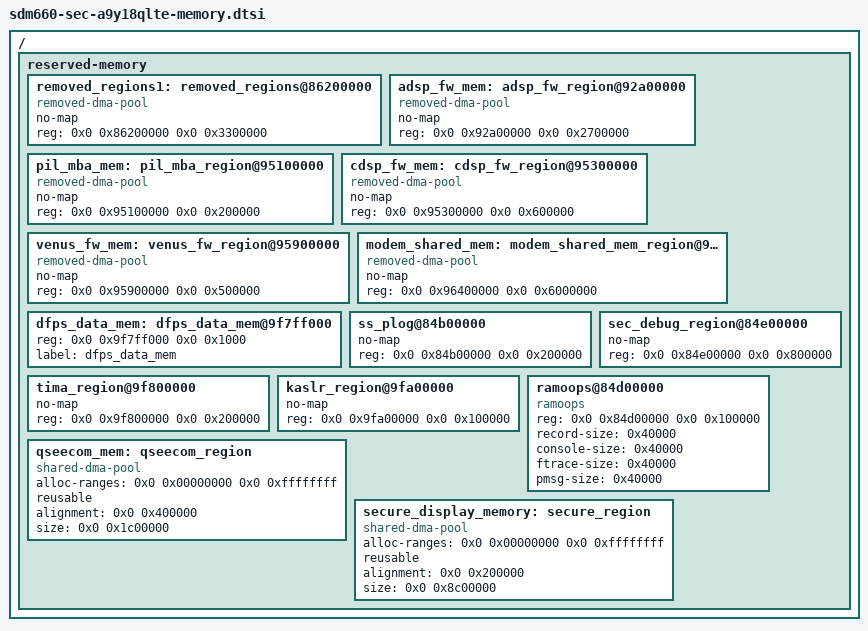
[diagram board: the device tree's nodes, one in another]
// SPDX-License-Identifier: GPL-2.0-only
/*
 * Samsung memory map for sdm660, taken from the 4.4 kernel
 * (sdm660-sec-common.dtsi). The firmware images and the bootloader
 * use these addresses, so they must match exactly.
 */

/ {
	reserved-memory {
		/* Samsung extends the removed region to 0x89500000 */
		/delete-node/ removed_regions@86200000;
		removed_regions1: removed_regions@86200000 {
			compatible = "removed-dma-pool";
			no-map;
			reg = <0x0 0x86200000 0x0 0x3300000>;
		};

		/delete-node/ adsp_fw_region@92a00000;
		adsp_fw_mem: adsp_fw_region@92a00000 {
			compatible = "removed-dma-pool";
			no-map;
			reg = <0x0 0x92a00000 0x0 0x2700000>;
		};

		/delete-node/ pil_mba_region@94800000;
		pil_mba_mem: pil_mba_region@95100000 {
			compatible = "removed-dma-pool";
			no-map;
			reg = <0x0 0x95100000 0x0 0x200000>;
		};

		/delete-node/ cdsp_fw_region@94a00000;
		cdsp_fw_mem: cdsp_fw_region@95300000 {
			compatible = "removed-dma-pool";
			no-map;
			reg = <0x0 0x95300000 0x0 0x600000>;
		};

		/delete-node/ venus_fw_region;
		venus_fw_mem: venus_fw_region@95900000 {
			compatible = "removed-dma-pool";
			no-map;
			reg = <0x0 0x95900000 0x0 0x500000>;
		};

		modem_shared_mem: modem_shared_mem_region@96400000 {
			compatible = "removed-dma-pool";
			no-map;
			reg = <0x0 0x96400000 0x0 0x6000000>;
		};

		/* Samsung bootloader writes the DFPS data here */
		/delete-node/ dfps_data_mem@0x9f800000;
		dfps_data_mem: dfps_data_mem@9f7ff000 {
			reg = <0x0 0x9f7ff000 0x0 0x1000>;
			label = "dfps_data_mem";
		};

		/* Used by the bootloader and TZ, keep them away from Linux */
		ss_plog@84b00000 {
			no-map;
			reg = <0x0 0x84b00000 0x0 0x200000>;
		};

		sec_debug_region@84e00000 {
			no-map;
			reg = <0x0 0x84e00000 0x0 0x800000>;
		};

		tima_region@9f800000 {
			no-map;
			reg = <0x0 0x9f800000 0x0 0x200000>;
		};

		kaslr_region@9fa00000 {
			no-map;
			reg = <0x0 0x9fa00000 0x0 0x100000>;
		};

		/* Kernel logs that survive a reboot, read them from recovery */
		ramoops@84d00000 {
			compatible = "ramoops";
			reg = <0x0 0x84d00000 0x0 0x100000>;
			record-size = <0x40000>;
			console-size = <0x40000>;
			ftrace-size = <0x40000>;
			pmsg-size = <0x40000>;
		};

		/delete-node/ qseecom_region;
		qseecom_mem: qseecom_region {
			compatible = "shared-dma-pool";
			alloc-ranges = <0x0 0x00000000 0x0 0xffffffff>;
			reusable;
			alignment = <0x0 0x400000>;
			size = <0x0 0x1c00000>;
		};

		/delete-node/ secure_region;
		secure_display_memory: secure_region {
			compatible = "shared-dma-pool";
			alloc-ranges = <0x0 0x00000000 0x0 0xffffffff>;
			reusable;
			alignment = <0x0 0x200000>;
			size = <0x0 0x8c00000>;
		};
	};
};
